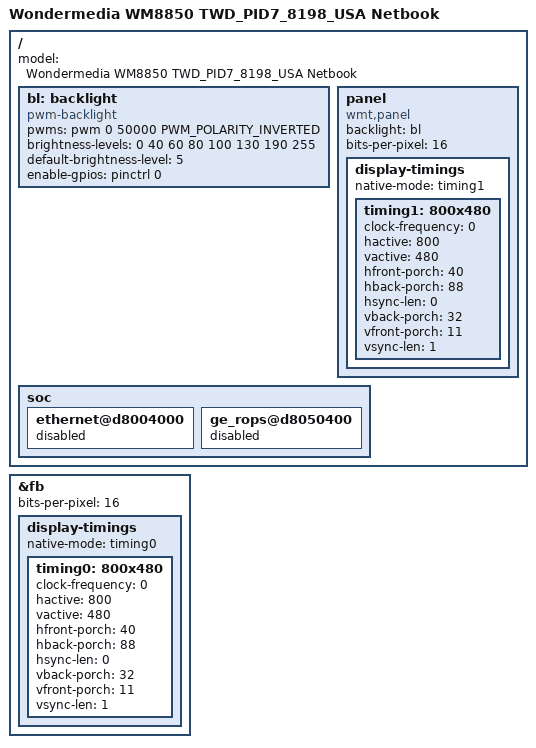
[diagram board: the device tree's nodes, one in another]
/dts-v1/;
/include/ "wm8850.dtsi"
#include <dt-bindings/pwm/pwm.h>

/ {
	model = "Wondermedia WM8850 TWD_PID7_8198_USA Netbook";

	bl: backlight {
		compatible = "pwm-backlight";
		pwms = <&pwm 0 50000 PWM_POLARITY_INVERTED>;

		brightness-levels = <0 40 60 80 100 130 190 255>;
		default-brightness-level = <5>;
		enable-gpios = <&pinctrl 0 0>;
	};

	panel {
		compatible = "wmt,panel";
		backlight = <&bl>;
		bits-per-pixel = <16>;
		display-timings {
			native-mode = <&timing1>;
			timing1: 800x480 {
				clock-frequency = <0>; /* unused but required */
				hactive = <800>;
				vactive = <480>;
				hfront-porch = <40>;
				hback-porch = <88>;
				hsync-len = <0>;
				vback-porch = <32>;
				vfront-porch = <11>;
				vsync-len = <1>;
			};
		};
	};

	soc {
		ethernet@d8004000 {
			status = "disabled";
		};

		ge_rops@d8050400 {
			status = "disabled";
		};
	};
};

&fb {
	bits-per-pixel = <16>;
	display-timings {
		native-mode = <&timing0>;
		timing0: 800x480 {
			clock-frequency = <0>; /* unused but required */
			hactive = <800>;
			vactive = <480>;
			hfront-porch = <40>;
			hback-porch = <88>;
			hsync-len = <0>;
			vback-porch = <32>;
			vfront-porch = <11>;
			vsync-len = <1>;
		};
	};
};
